# EMIF register map
Vendor: Texas Instruments
Peripheral module from a debugger description file (folder am437x).
Registers are 32-bit, access per field, no defined reset value unless marked. A register's access mark holds for its fields unless they carry their own. Offsets are as the file gives them; lines under a group give offsets from that group; [hi:lo] are bit positions; {n}, {i} and the like mark numbered series; 'fields as' and 'values as' point back to an identical list; <NAME> marks a mode.

## EMIF (part 1 of 2)
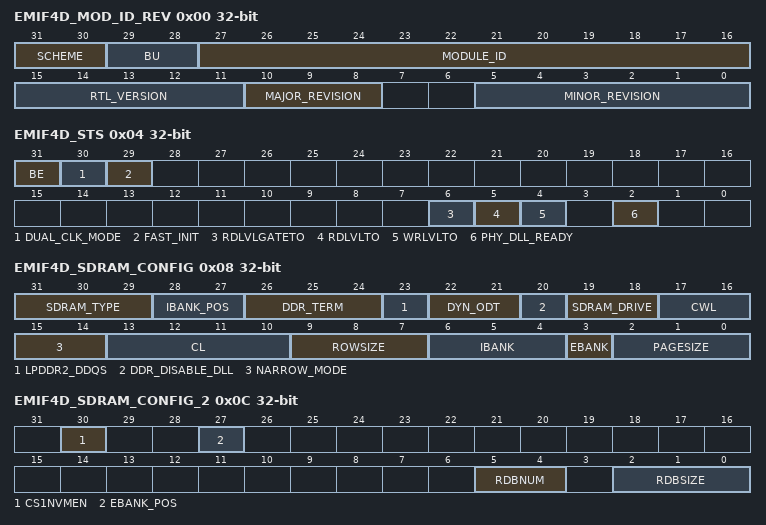
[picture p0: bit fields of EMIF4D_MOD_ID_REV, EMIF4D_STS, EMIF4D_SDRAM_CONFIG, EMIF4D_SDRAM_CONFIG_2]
0x00 EMIF4D_MOD_ID_REV ro
  [31:30] SCHEME — Used to distinguish between old and current schemes.
  [29:28] BU — Business Unit.
  [27:16] MODULE_ID — EMIF module ID.
  [15:11] RTL_VERSION
  [10:8] MAJOR_REVISION
  [5:0] MINOR_REVISION
0x04 EMIF4D_STS ro
  [31] BE — Big Endian. [[br]]Reflects the value on the config_big_endian port that defines whether the EMIF is in big or little endian mode.
  [30] DUAL_CLK_MODE — Dual Clock mode. [[br]]Reflects the value on the config_dual_clk_mode port that defines whether the ocp_clk and m_clk are asynchronous.
  [29] FAST_INIT — Fast Init. [[br]]Reflects the value on the config_fast_init port that defines whether the EMIF fast initialization mode has been enabled.
  [6] RDLVLGATETO — Read DQS Gate Training Timeout. [[br]]Value of 1 indicates read DQS gate training has timed out because read DQS gate training done was not received from the PHY.
  [5] RDLVLTO — Read Data Eye Training Timeout. [[br]]Value of 1 indicates read data eye training has timed out because read data eye training done was not received from the PHY.
  [4] WRLVLTO — Write Leveling Timeout. [[br]]Value of 1 indicates write leveling has timed out because write leveling done was not received from the PHY.
  [2] PHY_DLL_READY — DDR PHY Ready. [[br]]Reflects the value on the phy_ready port (active high) that defines whether the DDR PHY is ready for normal operation.
0x08 EMIF4D_SDRAM_CONFIG rw
  [31:29] SDRAM_TYPE — SDRAM Type selection. [[br]]Set to 3 for DDR3. [[br]]Set to 4 for LPDDR2. [[br]]All other values are reserved.
  [28:27] IBANK_POS — Internal bank position. [[br]]Set to 0 to assign internal bank address bits from lower OCP address bits as shown in tables. [[br]]Set to 1, 2, or 3 to assign internal bank address bits from higher OCP address bits as shown in tables.
  [26:24] DDR_TERM — DDR3 termination resistor value. [[br]]Set to 0 to disable termination. [[br]]Set to 1 for RZQ/4. [[br]]Set to 2 for RZQ/2. [[br]]Set to 3 for RZQ/6. [[br]]Set to 4 for RZQ/12. [[br]]Set to 5 for RZQ/8. [[br]]All other values are reserved.
  [23] LPDDR2_DDQS — LPDDR2 differential DQS enable. [[br]]Set to 0 for single ended DQS. [[br]]Set to 1 for differential DQS.
  [22:21] DYN_ODT — DDR3 Dynamic ODT. [[br]]Set to 0 to turn off dynamic ODT. [[br]]Set to 1 for RZQ/4 and set to 2 for RZQ/2. [[br]]All other values are reserved.
  [20] DDR_DISABLE_DLL — Disable DLL select. [[br]]Set to 1 to disable DLL inside SDRAM.
  [19:18] SDRAM_DRIVE — SDRAM drive strength. [[br]]For DDR3, set to 0 for RZQ/6 and set to 1 for RZQ/7. [[br]]All other values are reserved.
  [17:16] CWL — DDR3 CAS Write latency. [[br]]Value of 0, 1, 2, and 3 (CAS write latency of 5, 6, 7, and 8) are supported. [[br]]Use the lowest value supported for best performance. [[br]]All other values are reserved.
  [15:14] NARROW_MODE — SDRAM data bus width. [[br]]Set to 0 for 32 bit and set to 1 for 16 bit. [[br]]All other values are reserved.
  [13:10] CL — CAS Latency. [[br]]The value of this field defines the CAS latency to be used when accessing connected SDRAM devices. [[br]]Value of 2, 4, 6, 8, 10, 12, and 14 (CAS latency of 5, 6, 7, 8, 9, 10, and 11) are supported for DDR3. [[br]]Value of 3, 4, 5, 6, 7, and 8 (CAS latency of 3, 4, 5, 6, 7, and 8) are supported for LPDDR2 SDRAM. [[br]]All other values are reserved.
  [9:7] ROWSIZE — Row Size. [[br]]Defines the number of row address bits of connected SDRAM devices. [[br]]Set to 0 for 9 row bits, set to 1 for 10 row bits, set to 2 for 11 row bits, set to 3 for 12 row bits, set to 4 for 13 row bits, set to 5 for 14 row bits, set to 6 for 15 row bits, and set to 7 for 16 row bits. [[br]]This field is only used when reg_ibank_pos field in SDRAM Config register is set to 1, 2, or 3, or reg_ebank_pos field in SDRAM Config 2 register is set to 1.
  [6:4] IBANK — Internal Bank setup. [[br]]Defines number of banks inside connected SDRAM devices. [[br]]Set to 0 for 1 bank, set to 1 for 2 banks, set to 2 for 4 banks, and set to 3 for 8 banks. [[br]]All other values are reserved.
  [3] EBANK — External chip select setup. [[br]]Defines whether SDRAM accesses will use 1 or 2 chip select lines. [[br]]Set to 0 to use pad_cs_o_n[0] only. [[br]]Set to 1 to use pad_cs_o_n[[br]][1:0]. [[br]]This bit will automaticlly be set to 0 if reg_cs1nvmen field in the LPDDR2 NVM is set to 1.
  [2:0] PAGESIZE — Page Size. [[br]]Defines the internal page size of connected SDRAM devices. [[br]]Set to 0 for [[br]]256-word page (8 column bits), set to 1 for [[br]]512-word page (9 column bits), set to 2 for [[br]]1024-word page (10 column bits), and set to 3 for [[br]]2048-word page (11 column bits). [[br]]All other values are reserved.
0x0C EMIF4D_SDRAM_CONFIG_2
  [30] CS1NVMEN rw — CS1 LPDDR2 NVM enable. [[br]]Set to 1 if LPDDR2 NVM is connected to CS1. [[br]]This bit will automatically be set to 0 if reg_sdram_type field in the SDRAM Config register is not set to LPDDR2.
  [27] EBANK_POS rw — External bank position. [[br]]Set to 0 to assign external bank address bits from lower OCP address bits as shown in tables. [[br]]Set to 1 to assign external bank address bits from higher OCP address bits as shown in tables.
  [5:4] RDBNUM rw — Row Buffer setup. [[br]]Defines number of row buffers inside connected LPDDR2 NVM devices. [[br]]Set to 0 for 1 row buffer, set to 1 for 2 row buffers, set to 2 for 4 row buffers, and set to 3 for 8 row buffers. [[br]]All other values are reserved.
  [2:0] RDBSIZE rw — Row Data Buffer Size. [[br]]Defines the row data buffer size of connected LPDDR2 NVM devices. [[br]]Set to 0 for 32 bytes, set to 1 for 64 bytes, set to 2 for 128 bytes, set to 3 for 256 bytes, set to 4 for 512 bytes, set to 5 for 1024 bytes, set to 6 for 2048 bytes, and set to 7 for 4096 bytes.
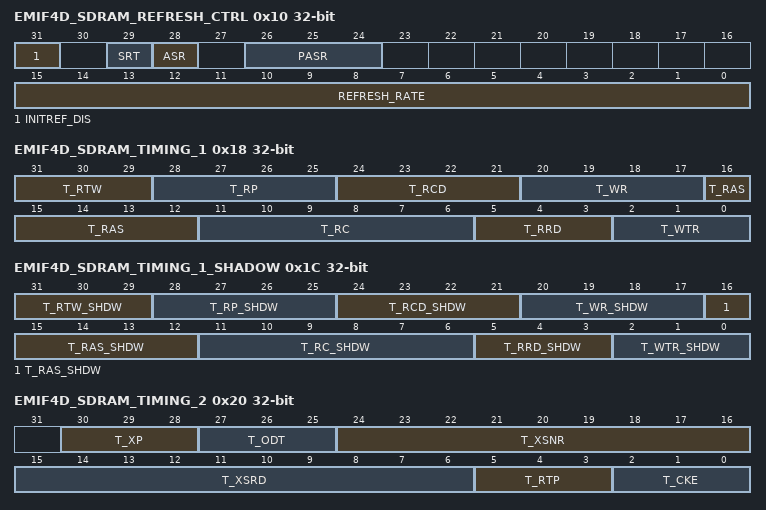
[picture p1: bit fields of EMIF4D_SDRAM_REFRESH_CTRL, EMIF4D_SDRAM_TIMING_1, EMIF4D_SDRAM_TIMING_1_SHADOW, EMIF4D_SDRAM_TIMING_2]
0x10 EMIF4D_SDRAM_REFRESH_CTRL
  [31] INITREF_DIS rw — Initialization and Refresh disable. [[br]]When set to 1, EMIF will disable SDRAM initialization and refreshes, but will carry out SDRAM write/read transactions.
  [29] SRT rw — DDR3 Self Refresh temperature range. [[br]]Set to 0 for normal operating temperature range and set to 1 for extended operating temperature range when the reg_asr field is set to 0. [[br]]This bit must be set to 0 if the reg_asr field is set to 1. [[br]]A write to this field will cause the EMIF to start the SDRAM initialization sequence.
  [28] ASR rw — DDR3 Auto Self Refresh enable. [[br]]Set to 1 for auto Self Refresh enable. [[br]]Set to 0 for manual Self Refresh reference indicated by the reg_srt field. [[br]]A write to this field will cause the EMIF to start the SDRAM initialization sequence.
  [26:24] PASR rw — Partial Array Self Refresh. [[br]]These bits get loaded into the Extended Mode Register of DDR3 during initialization. [[br]]Set to 0 for full array, set to 1 or 5 for 1/2 array, set to 2 or 6 for 1/4 array, set to 3 or 7 for 1/8 array, and set to 4 for 3/4 array to be refreshed. [[br]]All other values are reserved. [[br]]A write to this field will cause the EMIF to start the SDRAM initialization sequence.
  [15:0] REFRESH_RATE rw — Refresh Rate. [[br]]Value in this field is used to define the rate at which connected SDRAM devices will be refreshed. [[br]]SDRAM refresh rate = EMIF rate / reg_refresh_rate where EMIF rate is equal to m_clk rate. [[br]]If reg_refresh_rate < (8*reg_t_rfc)+reg_t_rp+reg_t_rcd+20 then it will be loaded with (8*reg_t_rfc)+reg_t_rp+reg_t_rcd+20. [[br]]This is done to avoid lock-up situations when illegal values are programmed.
0x14 EMIF4D_SDRAM_REFRESH_CTRL_SHADOW
  [15:0] REFRESH_RATE_SHDW rw — Shadow field for reg_refresh_rate. [[br]]This field is loaded into reg_refresh_rate field in SDRAM Refresh Control register when SIdleAck is asserted. [[br]]This register is not auto corrected when the value is invalid.
0x18 EMIF4D_SDRAM_TIMING_1 rw
  [31:29] T_RTW — Minimum number of DDR clock cycles between Read to Write data phases, minus one.
  [28:25] T_RP — Minimum number of DDR clock cycles from Precharge to Activate or Refresh, minus one.
  [24:21] T_RCD — Minimum number of DDR clock cycles from Activate to Read or Write, minus one.
  [20:17] T_WR — Minimum number of DDR clock cycles from last Write transfer to Pre-charge, minus one.
  [16:12] T_RAS — Minimum number of DDR clock cycles from Activate to Pre-charge, minus one. [[br]]reg_t_ras >= reg_t_rcd.
  [11:6] T_RC — Minimum number of DDR clock cycles from Activate to Activate, minus one.
  [5:3] T_RRD — Minimum number of DDR clock cycles from Activate to Activate for a different bank, minus one. [[br]]For an [[br]]8-bank DDR3, this field must be equal to ((tFAW/(4*tCK))-1).
  [2:0] T_WTR — Minimum number of DDR clock cycles from last Write to Read, minus one.
0x1C EMIF4D_SDRAM_TIMING_1_SHADOW rw
  [31:29] T_RTW_SHDW — Shadow field for reg_t_rtw. [[br]]This field is loaded into reg_t_rtw field in SDRAM Timing 1 register when SIdleAck is asserted.
  [28:25] T_RP_SHDW — Shadow field for reg_t_rp. [[br]]This field is loaded into reg_t_rp field in SDRAM Timing 1 register when SIdleAck is asserted.
  [24:21] T_RCD_SHDW — Shadow field for reg_t_rcd. [[br]]This field is loaded into reg_t_rcd field in SDRAM Timing 1 register when SIdleAck is asserted.
  [20:17] T_WR_SHDW — Shadow field for reg_t_wr. [[br]]This field is loaded into reg_t_wr field in SDRAM Timing 1 register when SIdleAck is asserted.
  [16:12] T_RAS_SHDW — Shadow field for reg_t_ras. [[br]]This field is loaded into reg_t_ras field in SDRAM Timing 1 register when SIdleAck is asserted.
  [11:6] T_RC_SHDW — Shadow field for reg_t_rc. [[br]]This field is loaded into reg_t_rc field in SDRAM Timing 1 register when SIdleAck is asserted.
  [5:3] T_RRD_SHDW — Shadow field for reg_t_rrd. [[br]]This field is loaded into reg_t_rrd field in SDRAM Timing 1 register when SIdleAck is asserted.
  [2:0] T_WTR_SHDW — Shadow field for reg_t_wtr. [[br]]This field is loaded into reg_t_wtr field in SDRAM Timing 1 register when SIdleAck is asserted.
0x20 EMIF4D_SDRAM_TIMING_2
  [30:28] T_XP rw — Minimum number of DDR clock cycles from Powerdown exit to any command other than a Read command, minus one.
  [27:25] T_ODT rw — Minimum number of DDR clock cycles from ODT enable to write data driven for and DDR3. [[br]]reg_t_odt must be equal to tAOND.
  [24:16] T_XSNR rw — Minimum number of DDR clock cycles from Self-Refresh exit to any command other than a Read command, minus one.
  [15:6] T_XSRD rw — Minimum number of DDR clock cycles from Self-Refresh exit to a Read command, minus one.
  [5:3] T_RTP rw — Minimum number of DDR clock cycles from the last Read command to a Pre-charge command for DDR3, minus one.
  [2:0] T_CKE rw — Minimum number of DDR clock cycles between pad_cke_o changes, minus one.
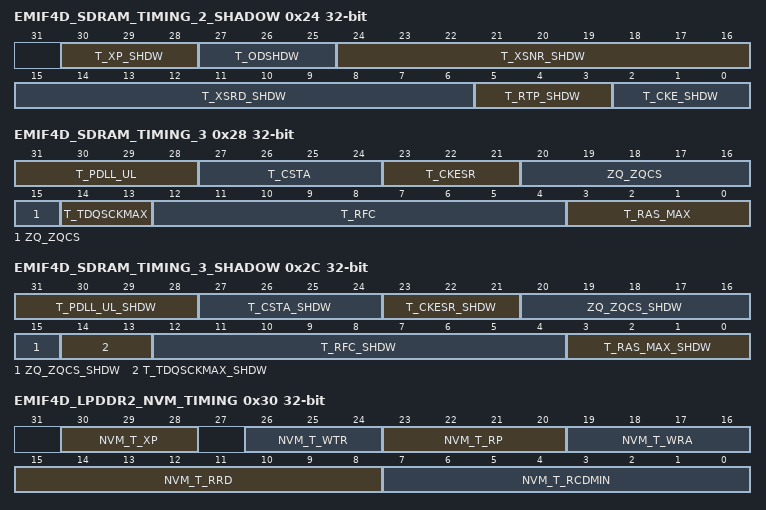
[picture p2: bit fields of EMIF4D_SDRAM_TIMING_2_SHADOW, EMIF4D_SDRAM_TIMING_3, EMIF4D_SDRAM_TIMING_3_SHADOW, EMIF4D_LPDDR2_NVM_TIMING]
0x24 EMIF4D_SDRAM_TIMING_2_SHADOW
  [30:28] T_XP_SHDW rw — Shadow field for reg_t_xp. [[br]]This field is loaded into reg_t_xp field in SDRAM Timing 2 register when SIdleAck is asserted.
  [27:25] T_ODSHDW rw — Shadow field for reg_t_odt. [[br]]This field is loaded into reg_t_odt field in SDRAM Timing 2 register when SIdleAck is asserted.
  [24:16] T_XSNR_SHDW rw — Shadow field for reg_t_xsnr. [[br]]This field is loaded into reg_t_xsnr field in SDRAM Timing 2 register when SIdleAck is asserted.
  [15:6] T_XSRD_SHDW rw — Shadow field for reg_t_xsrd. [[br]]This field is loaded into reg_t_xsrd field in SDRAM Timing 2 register when SIdleAck is asserted.
  [5:3] T_RTP_SHDW rw — Shadow field for reg_t_rtp. [[br]]This field is loaded into reg_t_rtp field in SDRAM Timing 2 register when SIdleAck is asserted.
  [2:0] T_CKE_SHDW rw — Shadow field for reg_t_cke. [[br]]This field is loaded into reg_t_cke field in SDRAM Timing 2 register when SIdleAck is asserted.
0x28 EMIF4D_SDRAM_TIMING_3 rw
  [31:28] T_PDLL_UL — Minimum number of DDR clock cycles for PHY DLL to unlock. [[br]]A value of N will be equal to N x 128 clocks.
  [27:24] T_CSTA — Minimum number of DDR clock cycles between write-to-write or read-to-read data phases to different chip selects, minus one.
  [23:21] T_CKESR — Minimum number of DDR clock cycles for which LPDDR2 must remain in Self Refresh, minus one.
  [20:15] ZQ_ZQCS — Number of DDR clock cycles for a ZQCS command, minus one.
  [14:13] T_TDQSCKMAX — Number of DDR clock cycles that satisfies tDQSCKmax for LPDDR2, minus one.
  [12:4] T_RFC — Minimum number of DDR clock cycles from Refresh or Load Mode to Refresh or Activate, minus one.
  [3:0] T_RAS_MAX — Maximum number of reg_refresh_rate intervals from Activate to Precharge command. [[br]]This field must be equal to ((tRASmax / tREFI)-1) rounded down to the next lower integer.
0x2C EMIF4D_SDRAM_TIMING_3_SHADOW rw
  [31:28] T_PDLL_UL_SHDW — Shadow field for reg_t_pdll_ul. [[br]]This field is loaded into reg_t_pdll_ul field in SDRAM Timing 3 register when SIdleAck is asserted.
  [27:24] T_CSTA_SHDW — Shadow field for reg_t_csta. [[br]]This field is loaded into reg_t_csta field in SDRAM Timing 3 register when SIdleAck is asserted.
  [23:21] T_CKESR_SHDW — Shadow field for reg_t_ckesr. [[br]]This field is loaded into reg_t_ckesr field in SDRAM Timing 3 register when SIdleAck is asserted.
  [20:15] ZQ_ZQCS_SHDW — Shadow field for reg_zq_zqcs. [[br]]This field is loaded into reg_t_tdqsckmax field in SDRAM Timing 3 register when SIdleAck is asserted.
  [14:13] T_TDQSCKMAX_SHDW — Shadow field for reg_t_tdqsckmax. [[br]]This field is loaded into reg_t_tdqsckmax field in SDRAM Timing 3 register when SIdleAck is asserted.
  [12:4] T_RFC_SHDW — Shadow field for reg_t_rfc. [[br]]This field is loaded into reg_t_rfc field in SDRAM Timing 3 register when SIdleAck is asserted.
  [3:0] T_RAS_MAX_SHDW — Shadow field for reg_t_ras_max. [[br]]This field is loaded into reg_t_ras_max field in SDRAM Timing 3 register when SIdleAck is asserted.
0x30 EMIF4D_LPDDR2_NVM_TIMING
  [30:28] NVM_T_XP rw — Minimum number of DDR clock cycles from Powerdown exit to any command, minus one.
  [26:24] NVM_T_WTR rw — Minimum number of DDR clock cycles from last Write to Read, minus one.
  [23:20] NVM_T_RP rw — Minimum number of DDR clock cycles from Preactive to Activate, minus one.
  [19:16] NVM_T_WRA rw — Minimum number of DDR clock cycles from last Write transfer to Activate, minus one.
  [15:8] NVM_T_RRD rw — Minimum number of DDR clock cycles from Activate to Activate for a different bank, minus one.
  [7:0] NVM_T_RCDMIN rw — Minimum number of DDR clock cycles from Activate to Read or Write, minus one.
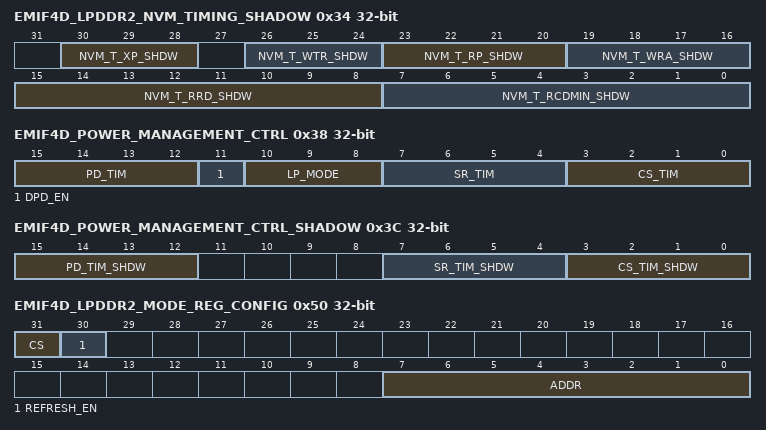
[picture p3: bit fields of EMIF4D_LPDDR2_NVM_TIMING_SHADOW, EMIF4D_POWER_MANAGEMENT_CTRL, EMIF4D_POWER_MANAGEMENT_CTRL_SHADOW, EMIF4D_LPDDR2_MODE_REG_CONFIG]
0x34 EMIF4D_LPDDR2_NVM_TIMING_SHADOW
  [30:28] NVM_T_XP_SHDW rw — Shadow field for reg_nvm_t_xp. [[br]]This field is loaded into reg_nvm_t_xp field in LPDDR2 NVM Timing register when SIdleAck is asserted.
  [26:24] NVM_T_WTR_SHDW rw — Shadow field for reg_nvm_t_wtr. [[br]]This field is loaded into reg_nvm_t_wtr field in LPDDR2 NVM Timing register when SIdleAck is asserted.
  [23:20] NVM_T_RP_SHDW rw — Shadow field for reg_nvm_t_rp. [[br]]This field is loaded into reg_nvm_t_rp field in LPDDR2 NVM Timing register when SIdleAck is asserted.
  [19:16] NVM_T_WRA_SHDW rw — Shadow field for reg_nvm_t_wra. [[br]]This field is loaded into reg_nvm_t_wra field in LPDDR2 NVM Timing register when SIdleAck is asserted.
  [15:8] NVM_T_RRD_SHDW rw — Shadow field for reg_nvm_t_rrd. [[br]]This field is loaded into reg_nvm_t_rrd field in LPDDR2 NVM Timing register when SIdleAck is asserted.
  [7:0] NVM_T_RCDMIN_SHDW rw — Shadow field for reg_nvm_t_rcdmin. [[br]]This field is loaded into reg_nvm_t_rcdmin field in LPDDR2 NVM Timing register when SIdleAck is asserted.
0x38 EMIF4D_POWER_MANAGEMENT_CTRL
  [15:12] PD_TIM rw — Power Mangement timer for Power-Down. [[br]]The EMIF will put the external SDRAM in Power-Down mode after the EMIF is idle for these number of DDR clock cycles and if reg_lp_mode field is set to 4. [[br]]Set to 0 to immediately enter Power-Down mode. [[br]]Set to 1 for 16 clocks, set to 2 for 32 clocks, set to 3 for 64 clocks, set to 4 for 128 clocks, set to 5 for 256 clocks, set to 6 for 512 clocks, set to 7 for 1024 clocks, set to 8 for 2048 clocks, set to 9 for 4096 clocks, set to 10 for 8192 clocks, set to 11 for 16384 clocks, set to 12 for 32768 clocks, set to 13 for 65536 clocks, set to 14 for 131072 clocks, and set to 15 for 262144 clocks.
  [11] DPD_EN rw — Deep Power Down enable. [[br]]Set to 0 for normal operation. [[br]]Set to 1 to enter deep power down mode. [[br]]This mode will override the reg_lp_mode field setting.
  [10:8] LP_MODE rw — Automatic Power Management enable. [[br]]Set to 1 for Clock Stop, set to 2 for Self Refresh, and set to 4 for Power-Down. [[br]]All other values will disable automatic power management.
  [7:4] SR_TIM rw — Power Mangement timer for Self Refresh. [[br]]The EMIF will put the external SDRAM in Self Refresh mode after the EMIF is idle for these number of DDR clock cycles and if reg_lp_mode field is set to 2. [[br]]Set to 0 to immediately enter Self Refresh mode. [[br]]Set to 1 for 16 clocks, set to 2 for 32 clocks, set to 3 for 64 clocks, set to 4 for 128 clocks, set to 5 for 256 clocks, set to 6 for 512 clocks, set to 7 for 1024 clocks, set to 8 for 2048 clocks, set to 9 for 4096 clocks, set to 10 for 8192 clocks, set to 11 for 16384 clocks, set to 12 for 32768 clocks, set to 13 for 65536 clocks, set to 14 for 131072 clocks, and set to 15 for 262144 clocks.
  [3:0] CS_TIM rw — Power Mangement timer for Clock Stop. [[br]]The EMIF will put the external SDRAM in Clock Stop mode after the EMIF is idle for these number of DDR clock cycles and if reg_lp_mode field is set to 1. [[br]]Set to 0 to immediately enter Clock Stop mode. [[br]]Set to 1 for 16 clocks, set to 2 for 32 clocks, set to 3 for 64 clocks, set to 4 for 128 clocks, set to 5 for 256 clocks, set to 6 for 512 clocks, set to 7 for 1024 clocks, set to 8 for 2048 clocks, set to 9 for 4096 clocks, set to 10 for 8192 clocks, set to 11 for 16384 clocks, set to 12 for 32768 clocks, set to 13 for 65536 clocks, set to 14 for 131072 clocks, and set to 15 for 262144 clocks.
0x3C EMIF4D_POWER_MANAGEMENT_CTRL_SHADOW
  [15:12] PD_TIM_SHDW rw — Shadow field for reg_pd_tim. [[br]]This field is loaded into reg_pd_tim field in Power Management Control register when SIdleAck is asserted.
  [7:4] SR_TIM_SHDW rw — Shadow field for reg_sr_tim. [[br]]This field is loaded into reg_sr_tim field in Power Management Control register when SIdleAck is asserted.
  [3:0] CS_TIM_SHDW rw — Shadow field for reg_cs_tim. [[br]]This field is loaded into reg_cs_tim field in Power Management Control register when SIdleAck is asserted.
0x40 EMIF4D_LPDDR2_MODE_REG_DATA
  [6:0] VALUE_0 rw — Mode register value.
0x50 EMIF4D_LPDDR2_MODE_REG_CONFIG
  [31] CS rw — Chip select to issue mode register command. [[br]]Set to 0 for CS0 and set to 1 for CS1.
  [30] REFRESH_EN rw — Refresh Enable after MRW write. [[br]]If a Mode Data register write occurs with this bit set to 1, the refresh operations will commence.
  [7:0] ADDR rw — Mode register address.
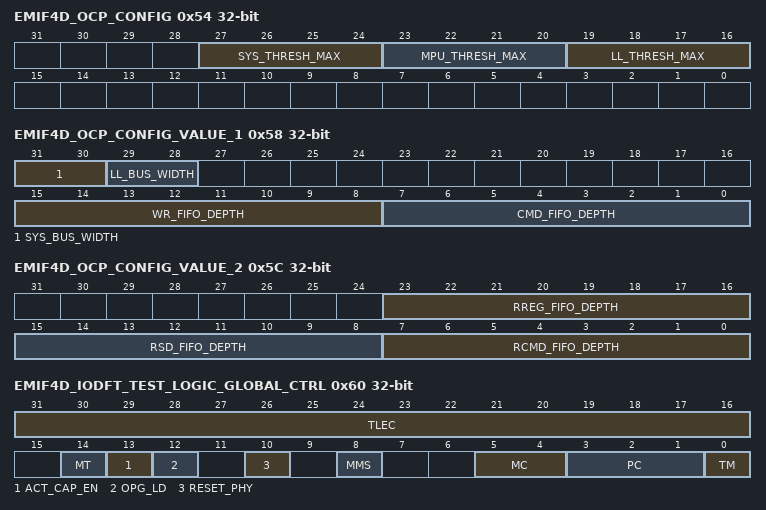
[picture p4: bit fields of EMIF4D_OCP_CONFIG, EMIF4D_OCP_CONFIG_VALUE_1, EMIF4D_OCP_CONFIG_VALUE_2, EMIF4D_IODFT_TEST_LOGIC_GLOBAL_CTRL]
0x54 EMIF4D_OCP_CONFIG
  [27:24] SYS_THRESH_MAX rw — System OCP Threshold Maximum. [[br]]The number of commands the system interface can consume in the command FIFO. [[br]]The value is used to determine when to stop future request, writing a zero will reserve no space for the associated interface. [[br]]In the event the value is set to zero and a request is seen for that interface, the command FIFO will assume a value of 1. [[br]]Since the low-latency interface has effectively a higher priority, the only way for the system interface to use all command FIFO entries is to set the reg_ll_thresh_max to zero.
  [23:20] MPU_THRESH_MAX rw — System MPU Threshold Maximum. [[br]]The number of commands the MPU interface can consume in the command FIFO. [[br]]The value is used to determine when to stop future request, writing a zero will reserve no space for the associated interface. [[br]]In the event the value is set to zero and a request is seen for that interface, the command FIFO will assume a value of 1. [[br]]Since the low-latency interface has effectively a higher priority, the only way for the mpu interface to use all command FIFO entries is to set the reg_ll_thresh_max to zero.
  [19:16] LL_THRESH_MAX rw — Low-latency OCP Threshold Maximum. [[br]]The number of commands the low latency interface can consume in the command FIFO. [[br]]The value is used to determine when to stop future request, writing a zero will reserve no space for the associated interface. [[br]]In the event the value is set to zero and a request is seen for that interface, the command FIFO will assume a value of 1.
0x58 EMIF4D_OCP_CONFIG_VALUE_1 ro
  [31:30] SYS_BUS_WIDTH — System OCP data bus width for a particular configuration. [[br]]0 = 32 bit wide, [[br]]1 = 64 bit wide, [[br]]2 = 128 bit wide, and [[br]]3 = 256 bit wide
  [29:28] LL_BUS_WIDTH — Low-latency OCP data bus width for a particular configuration. [[br]]0 = 32 bit wide, [[br]]1 = 64 bit wide, [[br]]2 = 128 bit wide, and [[br]]3 = 256 bit wide
  [15:8] WR_FIFO_DEPTH — Write Data FIFO depth for a particular configuration.
  [7:0] CMD_FIFO_DEPTH — Command FIFO depth for a particular configuration.
0x5C EMIF4D_OCP_CONFIG_VALUE_2 ro
  [23:16] RREG_FIFO_DEPTH — Register Read Data FIFO depth for a particular configuration.
  [15:8] RSD_FIFO_DEPTH — SDRAM Read Data FIFO depth for a particular configuration.
  [7:0] RCMD_FIFO_DEPTH — Read Command FIFO depth for a particular configuration.
0x60 EMIF4D_IODFT_TEST_LOGIC_GLOBAL_CTRL
  [31:16] TLEC rw — IODFT Test Logic Execution Counter. [[br]]Contains the number of cycle that the MISR signature will be accumulated. [[br]]Upon the expiration of the counter the MISR capture will be turned off.
  [14] MT rw — MISR on/off trigger command. [[br]]0h = inactive/no affect. [[br]]1h = MISR capture start on the first write or read command to the memory and continues to update the signature until reg_tlec expires, when mc = 3h. [[br]]1h = pattern generator starts on the first write or read command to the memory and continues to update the signature until reg_tlec expires, when reg_pc = 1h, 2h, 3h, 5h, 6h, or 7h. [[br]]These bits are cleared when reg_tlec expires.
  [13] ACT_CAP_EN rw — Active cycles capture enable. [[br]]If set to a 1 the MISRs and pattern generators will shift only during active cycles. [[br]]If set to a 0 the MISRs and pattern generators will shift every clock cycle.
  [12] OPG_LD rw — Load pattern generators' initial value. [[br]]Set to 1 to load an initial value in the pattern generators from reg_tlec.
  [10] RESET_PHY rw — Reset DDR PHY.
  [8] MMS rw — Chooses the source of the MISR input. [[br]]Set to 0 for output register, and set to 1 for input capture.
  [5:4] MC rw — MISR state. [[br]]Set to 0 to download results. [[br]]Set to 1 to hold current value. [[br]]Set to 2 to load initial value from reg_pc bits. [[br]]Set to 3 to enable MISR to capture signature.
  [3:1] PC rw — Pattern code. [[br]]Defines the type of pattern that is selected for the pattern generators. [[br]]Set to 0 for functional mode and set to 4 to hold current register value. [[br]]For output pattern generator, set to 1 for random XOR, set to 2 for random XNOR, and set to 3 for an 8 bit shifter. [[br]]For input pattern generator, set to 5 for random XOR, set to 6 for random XNOR, and set to 7 for an 8 bit shifter.
  [0] TM rw — Functional mode enable. [[br]]Set to 1 for functional mode, and set to 0 for IODFT mode.
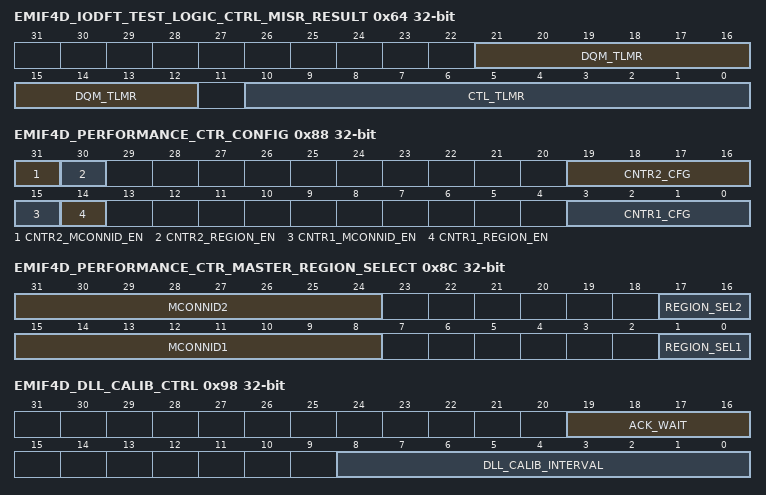
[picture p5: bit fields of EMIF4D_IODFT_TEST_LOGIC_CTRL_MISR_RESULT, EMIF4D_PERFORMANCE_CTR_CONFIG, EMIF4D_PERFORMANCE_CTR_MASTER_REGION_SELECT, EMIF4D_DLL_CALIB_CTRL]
0x64 EMIF4D_IODFT_TEST_LOGIC_CTRL_MISR_RESULT ro
  [21:12] DQM_TLMR — This contains the MISR result signature of a given test after the download function is executed. [[br]]This result is for the DQM signals.
  [10:0] CTL_TLMR — This contains the MISR result signature of a given test after the download function is executed. [[br]]This result is for the control signals.
0x68 EMIF4D_IODFT_TEST_LOGIC_ADDR_MISR_RESULT ro
  [20:0] ADDR_TLMR — This contains the MISR result signature of a given test after the download function is executed. [[br]]This result is for the address signals.
0x6C EMIF4D_IODFT_TEST_LOGIC_DATA_MISR_RESULT_1 ro
  [31:0] DATA_TLMR_31_0 — This contains the least significant bits of the MISR result signature of a given test after the download function is executed. [[br]]This result is for data bus.
0x70 EMIF4D_IODFT_TEST_LOGIC_DATA_MISR_RESULT_2 ro
  [31:0] DATA_TLMR_63_32 — This contains the middle bits of the MISR result signature of a given test after the download function is executed. [[br]]This result is for data bus.
0x74 EMIF4D_IODFT_TEST_LOGIC_DATA_MISR_RESULT_3 ro
  [2:0] DATA_TLMR_66_64 — This contains the most significant bits of the MISR result signature of a given test after the download function is executed. [[br]]This result is for data bus.
0x80 EMIF4D_PERFORMANCE_CTR_1 ro
  [31:0] CTR1 — 32 bit counter that can be configured as specified in the Performance Counter Config Register and Performance Counter Master Region Select Register.
0x84 EMIF4D_PERFORMANCE_CTR_2 ro
  [31:0] CTR2 — 32 bit counter that can be configured as specified in the Performance Counter Config Register and Performance Counter Master Region Select Register.
0x88 EMIF4D_PERFORMANCE_CTR_CONFIG
  [31] CNTR2_MCONNID_EN rw — MConnID filter enable for Performance Counter 2 register.
  [30] CNTR2_REGION_EN rw — Chip Select filter enable for Performance Counter 2 register.
  [19:16] CNTR2_CFG rw — Filter configuration for Performance Counter 2. [[br]]Refer to table for details.
  [15] CNTR1_MCONNID_EN rw — MConnID filter enable for Performance Counter 1 register.
  [14] CNTR1_REGION_EN rw — Chip Select filter enable for Performance Counter 1 register.
  [3:0] CNTR1_CFG rw — Filter configuration for Performance Counter 1. [[br]]Refer to table for details.
0x8C EMIF4D_PERFORMANCE_CTR_MASTER_REGION_SELECT
  [31:24] MCONNID2 rw — MConnID for Performance Counter 2 register.
  [17:16] REGION_SEL2 rw — MAddrSpace for Performance Counter 2 register.
  [15:8] MCONNID1 rw — MConnID for Performance Counter 1 register.
  [1:0] REGION_SEL1 rw — MAddrSpace for Performance Counter 1 register.
0x90 EMIF4D_PERFORMANCE_CTR_TIME ro
  [31:0] TOTAL_TIME — 32 bit counter that continuously counts number for m_clk cycles elapsed after EMIF is brought out of reset.
0x94 EMIF4D_MISC_REG
  [0] DLL_CALIB_OS rw — phy_dll_calib one shot : Setting bit to 1 generates a phy_pll_calib pulse. [[br]]Bit is self cleared when pll_calib gets generated
0x98 EMIF4D_DLL_CALIB_CTRL
  [19:16] ACK_WAIT rw — The ack_wait determines the required wait time after a phy_dll_calib is generated before another command can be sent
  [8:0] DLL_CALIB_INTERVAL rw — The dll_calib_interval field determines the interval between phy_dll_calib generation. [[br]]This value is multiplied by a precounter of 16 m_clk cycles. [[br]]Program this field one less the value you are targeting[[br]] program 1 to achieve interval of 2 (minimum interval supported). [[br]]Programming zero turns off function. [[br]]Note the final intervals between dll_calib generation is also a function of ACK_WAIT . [[br]]Final periodic interval is calculated by: ((dll_calib_interval+1)*16)+ACK_WAIT
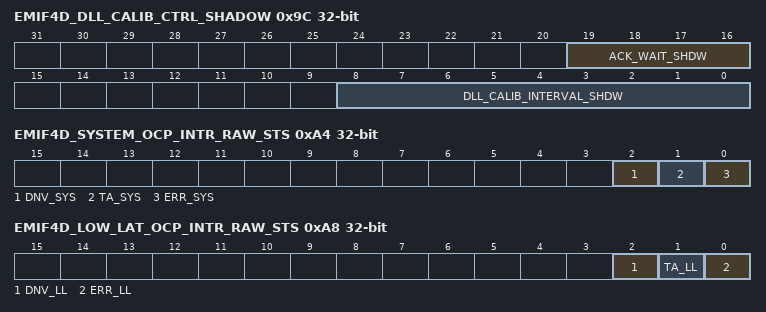
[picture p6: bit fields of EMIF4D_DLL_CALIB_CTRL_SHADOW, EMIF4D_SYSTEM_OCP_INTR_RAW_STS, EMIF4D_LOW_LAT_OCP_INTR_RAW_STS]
0x9C EMIF4D_DLL_CALIB_CTRL_SHADOW
  [19:16] ACK_WAIT_SHDW rw — Shadow field for ack_wait. [[br]]This field is loaded into ack_wait field in dll_calib_ctrl register when SIdleAck is asserted
  [8:0] DLL_CALIB_INTERVAL_SHDW rw — Shadow field for dll_calib_interval. [[br]]This field is loaded into dll_calib_interval field in the dll_calib_ctrl register when SIdleAck is asserted
0xA0 EMIF4D_END_OF_INTR
  [0] EOI rw — Software End Of Interrupt (EOI) control. [[br]]Write 0 for system OCP interrupt and write 1 for low-latency OCP interrupt. [[br]]This field always reads 0 (no EOI memory).
0xA4 EMIF4D_SYSTEM_OCP_INTR_RAW_STS
  [2] DNV_SYS rw — Raw status of system OCP interrupt for LPDDR2 NVM data not valid. [[br]]Write 1 to set the (raw) status, mostly for debug. [[br]]Writing a 0 has no effect.
  [1] TA_SYS rw — Raw status of system OCP interrupt for SDRAM temperature alert. [[br]]Write 1 to set the (raw) status, mostly for debug. [[br]]Writing a 0 has no effect.
  [0] ERR_SYS rw — Raw status of system OCP interrupt for command and address error. [[br]]Write 1 to set the (raw) status, mostly for debug. [[br]]Writing a 0 has no effect.
0xA8 EMIF4D_LOW_LAT_OCP_INTR_RAW_STS
  [2] DNV_LL rw — Raw status of low-latency OCP interrupt for LPDDR2 NVM data not valid. [[br]]Write 1 to set the (raw) status, mostly for debug. [[br]]Writing a 0 has no effect.
  [1] TA_LL rw — Raw status of low-latency OCP interrupt for SDRAM temperature alert. [[br]]Write 1 to set the (raw) status, mostly for debug. [[br]]Writing a 0 has no effect.
  [0] ERR_LL rw — Raw status of low-latency OCP interrupt for command and address error. [[br]]Write 1 to set the (raw) status, mostly for debug. [[br]]Writing a 0 has no effect.
